# MK24F12 register map
Vendor: Freescale Semiconductor, Inc.; Series: Kinetis_K; File version: 1.6
CPU: CM4 r0p1, little endian, no MPU, FPU, VTOR, 4 interrupt priority bits
Registers are 32-bit, read-write, reset 0x0 unless marked. A register's access mark holds for its fields unless they carry their own. Offsets are from the block's base; [hi:lo] are bit positions; {n}, {i} and the like mark numbered series; 'fields as' and 'values as' point back to an identical list.

## DAC0 — 12-Bit Digital-to-Analog Converter
Base 0x400CC000; register names take the prefix DAC0_
{0x0+2i} DAT{i}L (i=0..15) 8-bit — DAC Data Low Register
  [7:0] DATA0 — When the DAC buffer is not enabled, DATA[11:0] controls the output voltage based on the following formula: V out = V in * (1 + DACDAT0[11:0])/4096 When the DAC buffer is enabled, DATA is mapped to the 16-word buffer
{0x1+2i} DAT{i}H (i=0..15) 8-bit — DAC Data High Register
  [3:0] DATA1 — When the DAC Buffer is not enabled, DATA[11:0] controls the output voltage based on the following formula
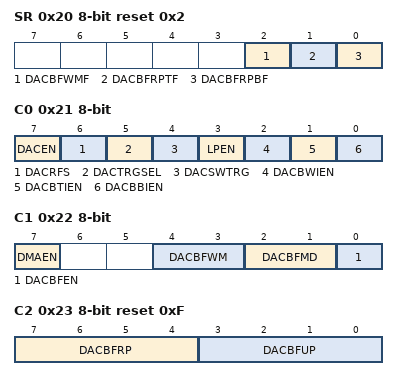
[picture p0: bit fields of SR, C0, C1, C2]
0x20 SR 8-bit reset 0x2 — DAC Status Register
  [2] DACBFWMF — DAC Buffer Watermark Flag
    0=The DAC buffer read pointer has not reached the watermark level; 1=The DAC buffer read pointer has reached the watermark level
  [1] DACBFRPTF — DAC Buffer Read Pointer Top Position Flag
    0=The DAC buffer read pointer is not zero; 1=The DAC buffer read pointer is zero
  [0] DACBFRPBF — DAC Buffer Read Pointer Bottom Position Flag
    0=The DAC buffer read pointer is not equal to C2[DACBFUP]; 1=The DAC buffer read pointer is equal to C2[DACBFUP]
0x21 C0 8-bit — DAC Control Register
  [7] DACEN — DAC Enable
    0=The DAC system is disabled; 1=The DAC system is enabled
  [6] DACRFS — DAC Reference Select
    0=The DAC selects DACREF_1 as the reference voltage; 1=The DAC selects DACREF_2 as the reference voltage
  [5] DACTRGSEL — DAC Trigger Select
    0=The DAC hardware trigger is selected; 1=The DAC software trigger is selected
  [4] DACSWTRG wo — DAC Software Trigger
    0=The DAC soft trigger is not valid; 1=The DAC soft trigger is valid
  [3] LPEN — DAC Low Power Control
    0=High-Power mode; 1=Low-Power mode
  [2] DACBWIEN — DAC Buffer Watermark Interrupt Enable
    0=The DAC buffer watermark interrupt is disabled; 1=The DAC buffer watermark interrupt is enabled
  [1] DACBTIEN — DAC Buffer Read Pointer Top Flag Interrupt Enable
    0=The DAC buffer read pointer top flag interrupt is disabled; 1=The DAC buffer read pointer top flag interrupt is enabled
  [0] DACBBIEN — DAC Buffer Read Pointer Bottom Flag Interrupt Enable
    0=The DAC buffer read pointer bottom flag interrupt is disabled; 1=The DAC buffer read pointer bottom flag interrupt is enabled
0x22 C1 8-bit — DAC Control Register 1
  [7] DMAEN — DMA Enable Select
    0=DMA is disabled; 1=DMA is enabled. When DMA is enabled, the DMA request will be generated by original interrupts. The interrupts will not be presented on this module at the same time.
  [4:3] DACBFWM — DAC Buffer Watermark Select
    0=1 word; 1=2 words; 2=3 words; 3=4 words
  [2:1] DACBFMD — DAC Buffer Work Mode Select
    0=Normal mode; 1=Swing mode; 2=One-Time Scan mode
  [0] DACBFEN — DAC Buffer Enable
    0=Buffer read pointer is disabled. The converted data is always the first word of the buffer.; 1=Buffer read pointer is enabled. The converted data is the word that the read pointer points to. It means converted data can be from any word of the buffer.
0x23 C2 8-bit reset 0xF — DAC Control Register 2
  [7:4] DACBFRP — DAC Buffer Read Pointer
  [3:0] DACBFUP — DAC Buffer Upper Limit

## DAC1 — 12-Bit Digital-to-Analog Converter
Base 0x400CD000; register names take the prefix DAC1_
Registers as DAC0.

## PTA — General Purpose Input/Output
Base 0x400FF000; register names take the prefix GPIOA_
0x00 PDOR — Port Data Output Register
  [31:0] PDO — Port Data Output
    0=Logic level 0 is driven on pin, provided pin is configured for general-purpose output; 1=Logic level 1 is driven on pin, provided pin is configured for general-purpose output
0x04 PSOR wo — Port Set Output Register
  [31:0] PTSO — Port Set Output
    0=Corresponding bit in PDORn does not change; 1=Corresponding bit in PDORn is set to logic 1
0x08 PCOR wo — Port Clear Output Register
  [31:0] PTCO — Port Clear Output
    0=Corresponding bit in PDORn does not change; 1=Corresponding bit in PDORn is cleared to logic 0
0x0C PTOR wo — Port Toggle Output Register
  [31:0] PTTO — Port Toggle Output
    0=Corresponding bit in PDORn does not change; 1=Corresponding bit in PDORn is set to the inverse of its existing logic state
0x10 PDIR ro — Port Data Input Register
  [31:0] PDI — Port Data Input
    0=Pin logic level is logic 0, or is not configured for use by digital function; 1=Pin logic level is logic 1
0x14 PDDR — Port Data Direction Register
  [31:0] PDD — Port Data Direction
    0=Pin is configured as general-purpose input, for the GPIO function; 1=Pin is configured as general-purpose output, for the GPIO function

## PTB — General Purpose Input/Output
Base 0x400FF040; register names take the prefix GPIOB_
Registers as PTA.

## PTC — General Purpose Input/Output
Base 0x400FF080; register names take the prefix GPIOC_
Registers as PTA; these are added or differ:
0x08 PCOR wo — Port Clear Output Register
  [31:0] PTCO — Port Clear Output
    0=Corresponding bit in PDORn does not change; 1=Corresponding bit in PDORn is cleared to logic 0

## PTD — General Purpose Input/Output
Base 0x400FF0C0; register names take the prefix GPIOD_
Registers as PTA.

## PTE — General Purpose Input/Output
Base 0x400FF100; register names take the prefix GPIOE_
Registers as PTA.

## CAU — Memory Mapped Cryptographic Acceleration Unit (MMCAU)
Base 0xE0081000
{0x0+4i} CAU_DIRECT{i} wo (i=0..15) — Direct access register {i}
  [31:0] CAU_DIRECT{i} — Direct register {i}
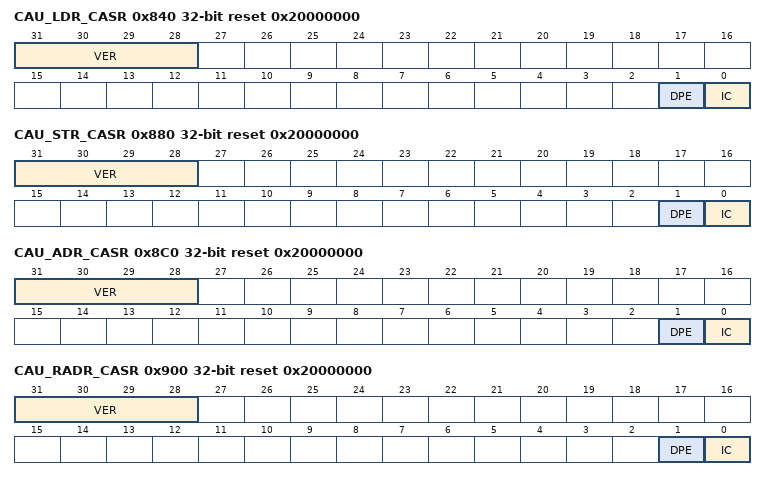
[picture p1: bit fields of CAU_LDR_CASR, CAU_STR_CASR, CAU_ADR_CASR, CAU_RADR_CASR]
0x840 CAU_LDR_CASR wo reset 0x20000000 — Status register - Load Register command
  [31:28] VER — CAU version
    1=Initial CAU version; 2=Second version, added support for SHA-256 algorithm.(This is the value on this device)
  [1] DPE
    0=No error detected; 1=DES key parity error detected
  [0] IC
    0=No illegal commands issued; 1=Illegal command issued
0x844 CAU_LDR_CAA wo — Accumulator register - Load Register command
  [31:0] ACC
{0x848+4i} CAU_LDR_CA{i} wo (i=0..8) — General Purpose Register {i} - Load Register command
0x880 CAU_STR_CASR ro reset 0x20000000 — Status register - Store Register command
  fields as CAU_LDR_CASR
0x884 CAU_STR_CAA ro — Accumulator register - Store Register command
  [31:0] ACC
{0x888+4i} CAU_STR_CA{i} ro (i=0..8) — General Purpose Register {i} - Store Register command
0x8C0 CAU_ADR_CASR wo reset 0x20000000 — Status register - Add Register command
  fields as CAU_LDR_CASR
0x8C4 CAU_ADR_CAA wo — Accumulator register - Add to register command
  [31:0] ACC
{0x8C8+4i} CAU_ADR_CA{i} wo (i=0..8) — General Purpose Register {i} - Add to register command
0x900 CAU_RADR_CASR wo reset 0x20000000 — Status register - Reverse and Add to Register command
  fields as CAU_LDR_CASR
0x904 CAU_RADR_CAA wo — Accumulator register - Reverse and Add to Register command
  [31:0] ACC
{0x908+4i} CAU_RADR_CA{i} wo (i=0..8) — General Purpose Register {i} - Reverse and Add to Register command
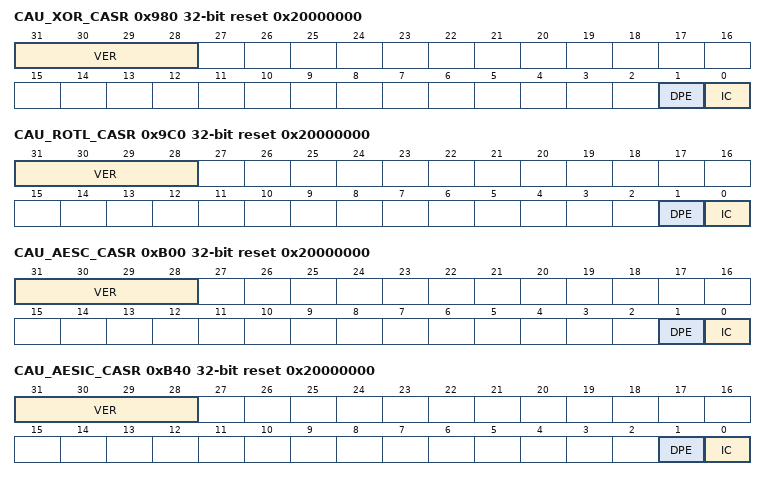
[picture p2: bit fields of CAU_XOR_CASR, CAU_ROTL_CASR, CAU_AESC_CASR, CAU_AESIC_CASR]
0x980 CAU_XOR_CASR wo reset 0x20000000 — Status register - Exclusive Or command
  fields as CAU_LDR_CASR
0x984 CAU_XOR_CAA wo — Accumulator register - Exclusive Or command
  [31:0] ACC
{0x988+4i} CAU_XOR_CA{i} wo (i=0..8) — General Purpose Register {i} - Exclusive Or command
0x9C0 CAU_ROTL_CASR wo reset 0x20000000 — Status register - Rotate Left command
  fields as CAU_LDR_CASR
0x9C4 CAU_ROTL_CAA wo — Accumulator register - Rotate Left command
  [31:0] ACC
{0x9C8+4i} CAU_ROTL_CA{i} wo (i=0..8) — General Purpose Register {i} - Rotate Left command
0xB00 CAU_AESC_CASR wo reset 0x20000000 — Status register - AES Column Operation command
  fields as CAU_LDR_CASR
0xB04 CAU_AESC_CAA wo — Accumulator register - AES Column Operation command
  [31:0] ACC
{0xB08+4i} CAU_AESC_CA{i} wo (i=0..8) — General Purpose Register {i} - AES Column Operation command
0xB40 CAU_AESIC_CASR wo reset 0x20000000 — Status register - AES Inverse Column Operation command
  fields as CAU_LDR_CASR
0xB44 CAU_AESIC_CAA wo — Accumulator register - AES Inverse Column Operation command
  [31:0] ACC
{0xB48+4i} CAU_AESIC_CA{i} wo (i=0..8) — General Purpose Register {i} - AES Inverse Column Operation command
